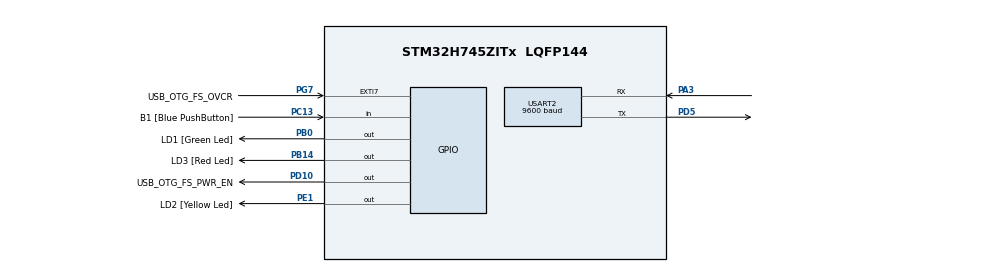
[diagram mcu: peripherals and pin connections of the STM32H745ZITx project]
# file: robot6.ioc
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CortexM4.IPs=FATFS_M4\:I,FREERTOS_M4\:I,IWDG2\:I,RCC,WWDG2\:I,DMA,BDMA,MDMA,NVIC2\:I,USART3,ETH,DEBUG,PDM2PCM_M4\:I,PWR,RESMGR_UTILITY,SYS_M4\:I,USB_DEVICE_M4\:I,USB_HOST_M4\:I,CORTEX_M4\:I,OPENAMP_M4\:I,VREFBUF
CortexM7.IPs=FATFS_M7\:I,FREERTOS_M7\:I,IWDG1\:I,RCC\:I,WWDG1\:I,DMA\:I,BDMA\:I,MDMA\:I,NVIC1\:I,SYS\:I,USART3\:I,USB_OTG_FS\:I,ETH\:I,CORTEX_M7\:I,DEBUG\:I,PDM2PCM_M7\:I,PWR\:I,RESMGR_UTILITY\:I,USB_DEVICE_M7\:I,USB_HOST_M7\:I,OPENAMP_M7\:I,VREFBUF\:I,USART2\:I
Mcu.Family=STM32H7
Mcu.Name=STM32H745ZITx
Mcu.Package=LQFP144
NVIC1.PriorityGroup=NVIC_PRIORITYGROUP_4
NVIC2.PriorityGroup=NVIC_PRIORITYGROUP_4
PA1.PinAttribute=CortexM7
PA1.Signal=ETH_REF_CLK
PA11.PinAttribute=CortexM7
PA11.Signal=USB_OTG_FS_DM
PA12.PinAttribute=CortexM7
PA12.Signal=USB_OTG_FS_DP
PA2.PinAttribute=CortexM7
PA2.Signal=ETH_MDIO
PA3.Mode=Asynchronous
PA3.PinAttribute=CortexM7
PA3.Signal=USART2_RX
PA7.PinAttribute=CortexM7
PA7.Signal=ETH_CRS_DV
PA8.PinAttribute=CortexM7
PA8.Signal=USB_OTG_FS_SOF
PA9.PinAttribute=CortexM7
PA9.Signal=USB_OTG_FS_VBUS
PB0.GPIO_Label=LD1 [Green Led]
PB0.PinAttribute=Free
PB0.Signal=GPIO_Output
PB13.PinAttribute=CortexM7
PB13.Signal=ETH_TXD1
PB14.GPIO_Label=LD3 [Red Led]
PB14.PinAttribute=Free
PB14.Signal=GPIO_Output
PC1.PinAttribute=CortexM7
PC1.Signal=ETH_MDC
PC13.GPIO_Label=B1 [Blue PushButton]
PC13.PinAttribute=Free
PC13.Signal=GPIO_Input
PC14-OSC32_IN\ (OSC32_IN).PinAttribute=CortexM7
PC14-OSC32_IN\ (OSC32_IN).Signal=RCC_OSC32_IN
PC15-OSC32_OUT\ (OSC32_OUT).PinAttribute=CortexM7
PC15-OSC32_OUT\ (OSC32_OUT).Signal=RCC_OSC32_OUT
PC4.PinAttribute=CortexM7
PC4.Signal=ETH_RXD0
PC5.PinAttribute=CortexM7
PC5.Signal=ETH_RXD1
PD10.GPIO_Label=USB_OTG_FS_PWR_EN
PD10.PinAttribute=Free
PD10.Signal=GPIO_Output
PD5.Mode=Asynchronous
PD5.PinAttribute=CortexM7
PD5.Signal=USART2_TX
PD8.GPIO_Label=STLINK_RX
PD8.PinAttribute=CortexM7
PD8.Signal=USART3_TX
PD9.GPIO_Label=STLINK_TX
PD9.PinAttribute=CortexM7
PD9.Signal=USART3_RX
PE1.GPIO_Label=LD2 [Yellow Led]
PE1.PinAttribute=Free
PE1.Signal=GPIO_Output
PG11.PinAttribute=CortexM7
PG11.Signal=ETH_TX_EN
PG13.PinAttribute=CortexM7
PG13.Signal=ETH_TXD0
PG7.GPIO_Label=USB_OTG_FS_OVCR
PG7.PinAttribute=Free
PG7.Signal=GPXTI7
PH0-OSC_IN\ (PH0).PinAttribute=CortexM7
PH0-OSC_IN\ (PH0).Signal=RCC_OSC_IN
PH1-OSC_OUT\ (PH1).PinAttribute=CortexM7
PH1-OSC_OUT\ (PH1).Signal=RCC_OSC_OUT
ProjectManager.HeapSize=0x200
ProjectManager.StackSize=0x400
ProjectManager.TargetToolchain=STM32CubeIDE
RCC.ADCFreq_Value=129000000
RCC.APB1Freq_Value=64000000
RCC.APB2Freq_Value=64000000
RCC.APB3Freq_Value=64000000
RCC.APB4Freq_Value=64000000
RCC.CortexFreq_Value=64000000
RCC.DIVM1=18
RCC.DIVM3=22
RCC.DIVN3=169
RCC.DIVQ3=4
RCC.HCLKFreq_Value=64000000
RCC.PLL2FRACN=0
RCC.PLL3FRACN=0
RCC.PLLFRACN=0
RCC.SYSCLKFreq_VALUE=64000000
RCC.SupplySource=PWR_DIRECT_SMPS_SUPPLY
RCC.USBCLockSelection=RCC_USBCLKSOURCE_PLL3
RCC.USBFreq_Value=122909090.9090909
USART2.BaudRate=9600
USART2.VirtualMode-Asynchronous=VM_ASYNC
VP_SYS_M4_VS_Systick.Mode=SysTick
board=NUCLEO-H745ZI-Q

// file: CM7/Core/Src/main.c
/* USER CODE BEGIN Header */
/**
 ******************************************************************************
 * @file           : main.c
 * @brief          : Main program body
 ******************************************************************************
 * @attention
 *
 * <h2><center>&copy; Copyright (c) 2021 STMicroelectronics.
 * All rights reserved.</center></h2>
 *
 * This software component is licensed by ST under BSD 3-Clause license,
 * the "License"; You may not use this file except in compliance with the
 * License. You may obtain a copy of the License at:
 *                        opensource.org/licenses/BSD-3-Clause
 *
 ******************************************************************************
 */
/* USER CODE END Header */
#include "main.h"

/* USER CODE BEGIN Includes */
#include "ServoControl.h"
#include <stdlib.h>
/* USER CODE END Includes */

/* USER CODE BEGIN PD */

#ifndef HSEM_ID_0
#define HSEM_ID_0 (0U) /* HW semaphore 0*/
#endif
/* USER CODE END PD */

UART_HandleTypeDef huart2;

void SystemClock_Config(void);
static void MX_GPIO_Init(void);
static void MX_USART2_UART_Init(void);

int main(void)
{
    /* USER CODE BEGIN Boot_Mode_Sequence_0 */
    int32_t timeout;
    /* USER CODE END Boot_Mode_Sequence_0 */

    /* USER CODE BEGIN Boot_Mode_Sequence_1 */
    /* Wait until CPU2 boots and enters in stop mode or timeout*/
    timeout = 0xFFFF;
    while ((__HAL_RCC_GET_FLAG(RCC_FLAG_D2CKRDY) != RESET) && (timeout-- > 0))
        ;
    if (timeout < 0) {
        Error_Handler();
    }
    /* USER CODE END Boot_Mode_Sequence_1 */
    /* MCU Configuration--------------------------------------------------------*/

    /* Reset of all peripherals, Initializes the Flash interface and the Systick. */
    HAL_Init();

    /* Configure the system clock */
    SystemClock_Config();
    /* USER CODE BEGIN Boot_Mode_Sequence_2 */
    /* When system initialization is finished, Cortex-M7 will release Cortex-M4 by means of
    HSEM notification */
    /*HW semaphore Clock enable*/
    __HAL_RCC_HSEM_CLK_ENABLE();
    /*Take HSEM */
    HAL_HSEM_FastTake(HSEM_ID_0);
    /*Release HSEM in order to notify the CPU2(CM4)*/
    HAL_HSEM_Release(HSEM_ID_0, 0);
    /* wait until CPU2 wakes up from stop mode */
    timeout = 0xFFFF;
    while ((__HAL_RCC_GET_FLAG(RCC_FLAG_D2CKRDY) == RESET) && (timeout-- > 0))
        ;
    if (timeout < 0) {
        Error_Handler();
    }
    /* USER CODE END Boot_Mode_Sequence_2 */

    /* Initialize all configured peripherals */
    MX_GPIO_Init();
    MX_USART2_UART_Init();

    /* Infinite loop */
    /* USER CODE BEGIN WHILE */
    robotInit(&huart2, 2000);
    robot_putDown(&huart2, 1000);
    while (1) {
        /* USER CODE END WHILE */

        /* USER CODE BEGIN 3 */
        // example 1
        // robotInit(&huart2, 2000);

        // robot_putDown(&huart2, 1000);
        // robotRotate(&huart2, 1000, 1, 2000);
        // robotRotate(&huart2, 1000, 2, 2000);

        // robot_pcikUp(&huart2, 1000);
        // robotRotate(&huart2, 1000, 1, 1500);
        // robotRotate(&huart2, 1000, 2, 1500);

        // example 2
        // robotInit(&huart2, 2000);

        // uint32_t servo_list[3] = {1, 2, 6};
        // uint32_t servo_pwm_list[3] = {2000, 2000, 950};
        // robot_control_cmd(&huart2, 3, 1000, servo_list, servo_pwm_list);

        // uint32_t servo_list2[3] = {1, 2, 6};
        // uint32_t servo_pwm_list2[3] = {1500, 1500, 1700};
        // robot_control_cmd(&huart2, 3, 1000, servo_list2, servo_pwm_list2);

        // my
        // TODO. TOP2500 水平1500 BUTTON500

        uint32_t servo_list[] = {2, 3, 4};
        uint32_t servo_pwm_list[] = {1950, 1000, 1300};
        robot_control_cmd(&huart2, 3, 1000, servo_list, servo_pwm_list);

        robot_pcikUp(&huart2, 1000);

        robotRotate(&huart2, 1000, 2, 1800);

        robot_putDown(&huart2, 1000);

        uint32_t servo_list2[] = {2, 3, 4};
        uint32_t servo_pwm_list2[] = {1500, 1500, 1500};
        robot_control_cmd(&huart2, 3, 1000, servo_list2, servo_pwm_list2);
    }
    /* USER CODE END 3 */
}

void SystemClock_Config(void)
{
    RCC_OscInitTypeDef RCC_OscInitStruct = {0};
    RCC_ClkInitTypeDef RCC_ClkInitStruct = {0};
    RCC_PeriphCLKInitTypeDef PeriphClkInitStruct = {0};

    /** Supply configuration update enable
     */
    HAL_PWREx_ConfigSupply(PWR_DIRECT_SMPS_SUPPLY);
    /** Configure the main internal regulator output voltage
     */
    __HAL_PWR_VOLTAGESCALING_CONFIG(PWR_REGULATOR_VOLTAGE_SCALE3);

    while (!__HAL_PWR_GET_FLAG(PWR_FLAG_VOSRDY)) {
    }
    /** Initializes the RCC Oscillators according to the specified parameters
     * in the RCC_OscInitTypeDef structure.
     */
    RCC_OscInitStruct.OscillatorType = RCC_OSCILLATORTYPE_HSI;
    RCC_OscInitStruct.HSIState = RCC_HSI_DIV1;
    RCC_OscInitStruct.HSICalibrationValue = RCC_HSICALIBRATION_DEFAULT;
    RCC_OscInitStruct.PLL.PLLState = RCC_PLL_NONE;
    if (HAL_RCC_OscConfig(&RCC_OscInitStruct) != HAL_OK) {
        Error_Handler();
    }
    /** Initializes the CPU, AHB and APB buses clocks
     */
    RCC_ClkInitStruct.ClockType = RCC_CLOCKTYPE_HCLK | RCC_CLOCKTYPE_SYSCLK | RCC_CLOCKTYPE_PCLK1 |
                                  RCC_CLOCKTYPE_PCLK2 | RCC_CLOCKTYPE_D3PCLK1 | RCC_CLOCKTYPE_D1PCLK1;
    RCC_ClkInitStruct.SYSCLKSource = RCC_SYSCLKSOURCE_HSI;
    RCC_ClkInitStruct.SYSCLKDivider = RCC_SYSCLK_DIV1;
    RCC_ClkInitStruct.AHBCLKDivider = RCC_HCLK_DIV1;
    RCC_ClkInitStruct.APB3CLKDivider = RCC_APB3_DIV1;
    RCC_ClkInitStruct.APB1CLKDivider = RCC_APB1_DIV1;
    RCC_ClkInitStruct.APB2CLKDivider = RCC_APB2_DIV1;
    RCC_ClkInitStruct.APB4CLKDivider = RCC_APB4_DIV1;

    if (HAL_RCC_ClockConfig(&RCC_ClkInitStruct, FLASH_LATENCY_0) != HAL_OK) {
        Error_Handler();
    }
    PeriphClkInitStruct.PeriphClockSelection = RCC_PERIPHCLK_USART2;
    PeriphClkInitStruct.Usart234578ClockSelection = RCC_USART234578CLKSOURCE_D2PCLK1;
    if (HAL_RCCEx_PeriphCLKConfig(&PeriphClkInitStruct) != HAL_OK) {
        Error_Handler();
    }
}

static void MX_USART2_UART_Init(void)
{

    huart2.Instance = USART2;
    huart2.Init.BaudRate = 9600;
    huart2.Init.WordLength = UART_WORDLENGTH_8B;
    huart2.Init.StopBits = UART_STOPBITS_1;
    huart2.Init.Parity = UART_PARITY_NONE;
    huart2.Init.Mode = UART_MODE_TX_RX;
    huart2.Init.HwFlowCtl = UART_HWCONTROL_NONE;
    huart2.Init.OverSampling = UART_OVERSAMPLING_16;
    huart2.Init.OneBitSampling = UART_ONE_BIT_SAMPLE_DISABLE;
    huart2.Init.ClockPrescaler = UART_PRESCALER_DIV1;
    huart2.AdvancedInit.AdvFeatureInit = UART_ADVFEATURE_NO_INIT;
    if (HAL_UART_Init(&huart2) != HAL_OK) {
        Error_Handler();
    }
    if (HAL_UARTEx_SetTxFifoThreshold(&huart2, UART_TXFIFO_THRESHOLD_1_8) != HAL_OK) {
        Error_Handler();
    }
    if (HAL_UARTEx_SetRxFifoThreshold(&huart2, UART_RXFIFO_THRESHOLD_1_8) != HAL_OK) {
        Error_Handler();
    }
    if (HAL_UARTEx_DisableFifoMode(&huart2) != HAL_OK) {
        Error_Handler();
    }
}

static void MX_GPIO_Init(void)
{
    GPIO_InitTypeDef GPIO_InitStruct = {0};

    /* GPIO Ports Clock Enable */
    __HAL_RCC_GPIOC_CLK_ENABLE();
    __HAL_RCC_GPIOH_CLK_ENABLE();
    __HAL_RCC_GPIOA_CLK_ENABLE();
    __HAL_RCC_GPIOB_CLK_ENABLE();
    __HAL_RCC_GPIOD_CLK_ENABLE();
    __HAL_RCC_GPIOG_CLK_ENABLE();

    /*Configure GPIO pins : PC1 PC4 PC5 */
    GPIO_InitStruct.Pin = GPIO_PIN_1 | GPIO_PIN_4 | GPIO_PIN_5;
    GPIO_InitStruct.Mode = GPIO_MODE_AF_PP;
    GPIO_InitStruct.Pull = GPIO_NOPULL;
    GPIO_InitStruct.Speed = GPIO_SPEED_FREQ_LOW;
    GPIO_InitStruct.Alternate = GPIO_AF11_ETH;
    HAL_GPIO_Init(GPIOC, &GPIO_InitStruct);

    /*Configure GPIO pins : PA1 PA2 PA7 */
    GPIO_InitStruct.Pin = GPIO_PIN_1 | GPIO_PIN_2 | GPIO_PIN_7;
    GPIO_InitStruct.Mode = GPIO_MODE_AF_PP;
    GPIO_InitStruct.Pull = GPIO_NOPULL;
    GPIO_InitStruct.Speed = GPIO_SPEED_FREQ_LOW;
    GPIO_InitStruct.Alternate = GPIO_AF11_ETH;
    HAL_GPIO_Init(GPIOA, &GPIO_InitStruct);

    /*Configure GPIO pin : PB13 */
    GPIO_InitStruct.Pin = GPIO_PIN_13;
    GPIO_InitStruct.Mode = GPIO_MODE_AF_PP;
    GPIO_InitStruct.Pull = GPIO_NOPULL;
    GPIO_InitStruct.Speed = GPIO_SPEED_FREQ_LOW;
    GPIO_InitStruct.Alternate = GPIO_AF11_ETH;
    HAL_GPIO_Init(GPIOB, &GPIO_InitStruct);

    /*Configure GPIO pins : PD8 PD9 */
    GPIO_InitStruct.Pin = GPIO_PIN_8 | GPIO_PIN_9;
    GPIO_InitStruct.Mode = GPIO_MODE_AF_PP;
    GPIO_InitStruct.Pull = GPIO_NOPULL;
    GPIO_InitStruct.Speed = GPIO_SPEED_FREQ_LOW;
    GPIO_InitStruct.Alternate = GPIO_AF7_USART3;
    HAL_GPIO_Init(GPIOD, &GPIO_InitStruct);

    /*Configure GPIO pins : PA8 PA11 PA12 */
    GPIO_InitStruct.Pin = GPIO_PIN_8 | GPIO_PIN_11 | GPIO_PIN_12;
    GPIO_InitStruct.Mode = GPIO_MODE_AF_PP;
    GPIO_InitStruct.Pull = GPIO_NOPULL;
    GPIO_InitStruct.Speed = GPIO_SPEED_FREQ_LOW;
    GPIO_InitStruct.Alternate = GPIO_AF10_OTG1_FS;
    HAL_GPIO_Init(GPIOA, &GPIO_InitStruct);

    /*Configure GPIO pins : PG11 PG13 */
    GPIO_InitStruct.Pin = GPIO_PIN_11 | GPIO_PIN_13;
    GPIO_InitStruct.Mode = GPIO_MODE_AF_PP;
    GPIO_InitStruct.Pull = GPIO_NOPULL;
    GPIO_InitStruct.Speed = GPIO_SPEED_FREQ_LOW;
    GPIO_InitStruct.Alternate = GPIO_AF11_ETH;
    HAL_GPIO_Init(GPIOG, &GPIO_InitStruct);
}

void Error_Handler(void)
{
    __disable_irq();
    while (1) {
    }
}

/************************ (C) COPYRIGHT STMicroelectronics *****END OF FILE****/
